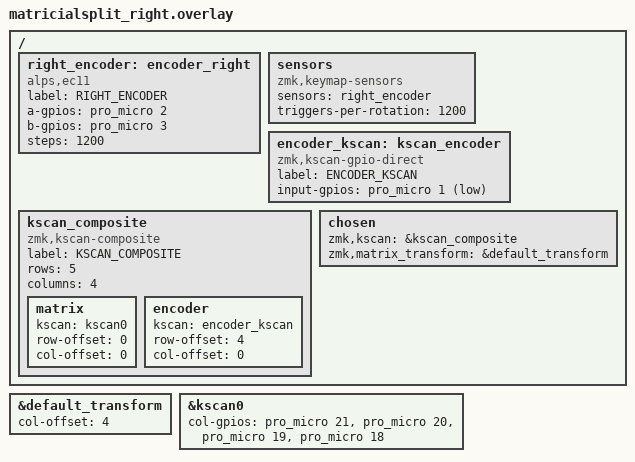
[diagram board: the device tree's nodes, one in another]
#include "matricialsplit.dtsi"

&default_transform {
    // Right side uses columns 4-7  
    col-offset = <4>;
};

&kscan0 {
    // Right side columns
    col-gpios
        = <&pro_micro 21 (GPIO_ACTIVE_HIGH | GPIO_PULL_DOWN)>
        , <&pro_micro 20 (GPIO_ACTIVE_HIGH | GPIO_PULL_DOWN)>
        , <&pro_micro 19 (GPIO_ACTIVE_HIGH | GPIO_PULL_DOWN)>
        , <&pro_micro 18 (GPIO_ACTIVE_HIGH | GPIO_PULL_DOWN)>
        ;
};

/ {
    // Encoder derecho KY-040
    right_encoder: encoder_right {
        compatible = "alps,ec11";
        label = "RIGHT_ENCODER";
        a-gpios = <&pro_micro 2 (GPIO_ACTIVE_HIGH | GPIO_PULL_UP)>;  // CLK
        b-gpios = <&pro_micro 3 (GPIO_ACTIVE_HIGH | GPIO_PULL_UP)>;  // DT
        steps = <1200>;  // Aumentar pasos para reducir sensibilidad (4x menos sensible)
        status = "okay";
    };

    // Sensor para el encoder derecho
    sensors {
        compatible = "zmk,keymap-sensors";
        sensors = <&right_encoder>;
        triggers-per-rotation = <1200>;  // Debe coincidir con steps
    };

    // Configuración del click del encoder como kscan adicional
    encoder_kscan: kscan_encoder {
        compatible = "zmk,kscan-gpio-direct";
        label = "ENCODER_KSCAN";
        input-gpios = <&pro_micro 1 (GPIO_ACTIVE_LOW | GPIO_PULL_UP)>;  // SW
    };

    // Combinar ambos kscan (matriz principal + encoder click)
    kscan_composite: kscan_composite {
        compatible = "zmk,kscan-composite";
        label = "KSCAN_COMPOSITE";
        rows = <5>;  // 5 filas para incluir encoder click
        columns = <4>;  // 4 columnas del lado derecho
        
        // Nodos hijos en lugar de propiedad kscan
        matrix {
            kscan = <&kscan0>;
            row-offset = <0>;
            col-offset = <0>;
        };
        
        encoder {
            kscan = <&encoder_kscan>;
            row-offset = <4>;
            col-offset = <0>;  // Encoder click en la columna 0 local (será RC(4,4) globalmente)
        };
    };

    // Actualizar chosen para usar el kscan composite
    chosen {
        zmk,kscan = &kscan_composite;
        zmk,matrix_transform = &default_transform;
    };
};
